# m52363b register map
Vendor: Elmos Semiconductor SE; Series: Integrated Driver; File version: 1.0
CPU: CM23 r1p0, little endian, MPU, no FPU, VTOR, 2 interrupt priority bits, 13 interrupts
Registers are 16-bit, read-write, reset 0x0 unless marked. A register's access mark holds for its fields unless they carry their own. Offsets are from the block's base; [hi:lo] are bit positions; {n}, {i} and the like mark numbered series; 'fields as' and 'values as' point back to an identical list.

## MOD_SECEXT — This instance contains registers for (core system level) module non-secure access protection
Base 0x45000020
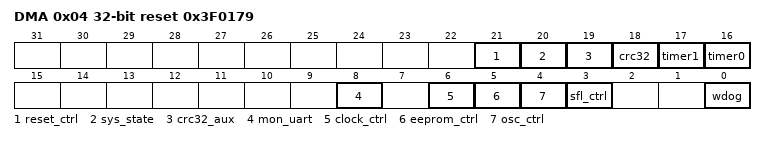
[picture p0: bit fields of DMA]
0x04 DMA 32-bit reset 0x3F0179
  [21] reset_ctrl — reset_ctrl bitfield
  [20] sys_state — sys_state bitfield
  [19] crc32_aux — crc32_aux bitfield
  [18] crc32 — crc32 bitfield
  [17] timer1 — timer1 bitfield
  [16] timer0 — timer0 bitfield
  [8] mon_uart — mon_uart bitfield
  [6] clock_ctrl — clock_ctrl bitfield
  [5] eeprom_ctrl — eeprom_ctrl bitfield
  [4] osc_ctrl — osc_ctrl bitfield
  [3] sfl_ctrl — sfl_ctrl bitfield
  [0] wdog — wdog bitfield

## MOD_SECEXT_CORE — This instance contains registers for (core level) module non-secure access protection
Base 0x45000028
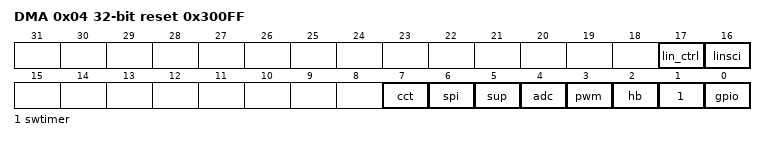
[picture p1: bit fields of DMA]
0x04 DMA 32-bit reset 0x300FF
  [17] lin_ctrl — lin_ctrl bitfield
  [16] linsci — linsci bitfield
  [7] cct — cct bitfield
  [6] spi — spi bitfield
  [5] sup — sup bitfield
  [4] adc — adc bitfield
  [3] pwm — pwm bitfield
  [2] hb — hb bitfield
  [1] swtimer — swtimer bitfield
  [0] gpio — gpio bitfield

## DMA_SEC_CRC16 — This instance contains registers for (core system level) DMA access protection.
Base 0x45000100
Same registers: DMA_SEC_CORE_LIN 0x45000180
0x00 AREA_BASE 32-bit
  [31:0] addr — addr bitfield
0x04 AREA_SIZE 32-bit
  [19:0] bytes — bytes bitfield
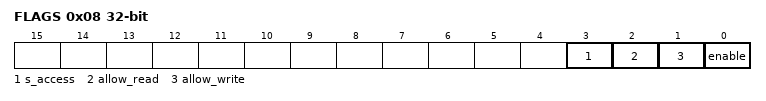
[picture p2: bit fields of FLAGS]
0x08 FLAGS 32-bit
  [3] s_access — s_access bitfield
  [2] allow_read — allow_read bitfield
  [1] allow_write — allow_write bitfield
  [0] enable — enable bitfield

## SEC_STATE — This instance contains registers for (core system level) DMA access error handling.
Base 0x45000200
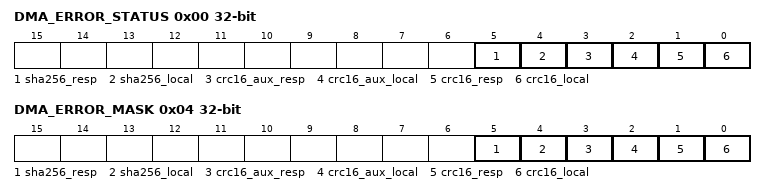
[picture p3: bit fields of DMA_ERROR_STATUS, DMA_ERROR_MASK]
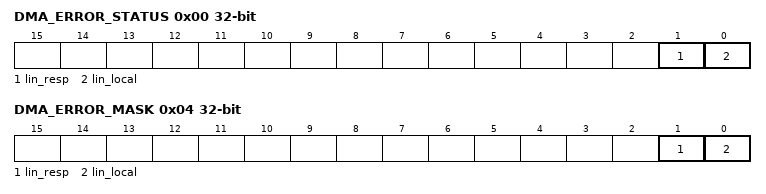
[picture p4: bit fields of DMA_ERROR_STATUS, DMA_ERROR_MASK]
0x00 DMA_ERROR_STATUS 32-bit
  [5] sha256_resp — sha256_resp bitfield
  [4] sha256_local — sha256_local bitfield
  [3] crc16_aux_resp — crc16_aux_resp bitfield
  [2] crc16_aux_local — crc16_aux_local bitfield
  [1] crc16_resp — crc16_resp bitfield
  [0] crc16_local — crc16_local bitfield
0x04 DMA_ERROR_MASK 32-bit
  fields as DMA_ERROR_STATUS

## SEC_STATE_CORE — This instance contains registers for (core level) DMA access error handling.
Base 0x45000210
0x00 DMA_ERROR_STATUS 32-bit
  [1] lin_resp — lin_resp bitfield
  [0] lin_local — lin_local bitfield
0x04 DMA_ERROR_MASK 32-bit
  fields as DMA_ERROR_STATUS

## SEC_VERSION
Base 0x45000220
0x00 VERSION 32-bit ro reset 0x1
  [31:0] version — version bitfield
0x04 MOD_SEC_VERSION 32-bit ro reset 0x1
  [31:0] version — version bitfield
0x08 MEM_SEC_VERSION 32-bit ro reset 0x1
  [31:0] version — version bitfield
0x0C DMA_SEC_VERSION 32-bit ro reset 0x1
  [31:0] version — version bitfield

## GPIO — GPIO module
Base 0x50000000
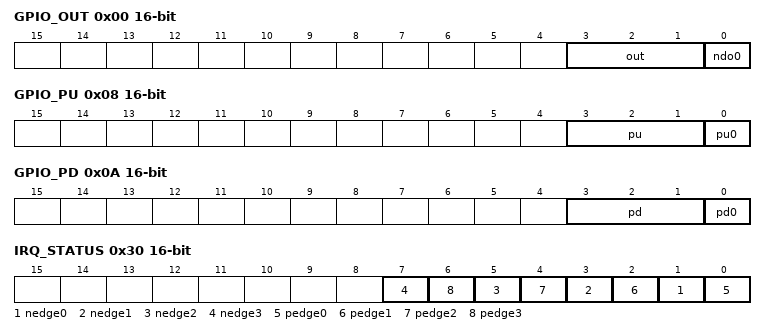
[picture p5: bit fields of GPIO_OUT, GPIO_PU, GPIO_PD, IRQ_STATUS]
0x00 GPIO_OUT
  [3:1] out — out bitfield
  [0] ndo0 — ndo0 bitfield
0x02 GPIO_OE
  [3:1] oe — oe bitfield
0x04 GPIO_IN ro
  [3:0] in — in bitfield
0x06 GPIO_DIG
  [3:0] dig — dig bitfield
0x08 GPIO_PU
  [3:1] pu — pu bitfield
  [0] pu0 — pu0 bitfield
0x0A GPIO_PD
  [3:1] pd — pd bitfield
  [0] pd0 — pd0 bitfield
0x0C TRIG_EDGE
  [3:0] te — te bitfield
0x0E CONFIG
  [2:0] set — set bitfield
0x30 IRQ_STATUS
  [2n+1] nedge{n} (n=0..3) — nedge{n} bitfield
  [2n] pedge{n} (n=0..3) — pedge{n} bitfield
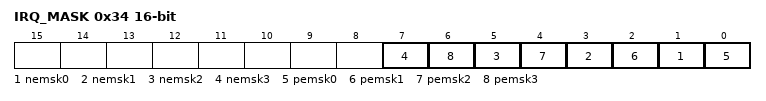
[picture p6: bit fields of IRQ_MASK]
0x34 IRQ_MASK
  [2n+1] nemsk{n} (n=0..3) — nemsk{n} bitfield
  [2n] pemsk{n} (n=0..3) — pemsk{n} bitfield
0x38 IRQ_VENABLE wo reset not defined
  [2:0] vno — vno bitfield
0x3A IRQ_VDISABLE wo reset not defined
  [2:0] vno — vno bitfield
0x3C IRQ_VMAX reset 0x8
  [3:0] vmax — vmax bitfield
0x3E IRQ_VNO reset 0x8
  [3:0] vno — vno bitfield

## SWTIMER — SWTIMER module
Base 0x50000100
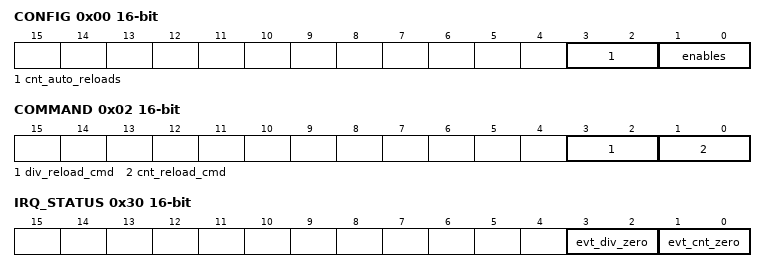
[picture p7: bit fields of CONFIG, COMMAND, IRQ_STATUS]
0x00 CONFIG
  [3:2] cnt_auto_reloads — cnt_auto_reloads bitfield
  [1:0] enables — enables bitfield
0x02 COMMAND wo reset not defined
  [3:2] div_reload_cmd — div_reload_cmd bitfield
  [1:0] cnt_reload_cmd — cnt_reload_cmd bitfield
0x04 CNT0_RELOAD
  [15:0] cnt_reload — cnt_reload bitfield
0x06 CNT1_RELOAD
  [15:0] cnt_reload — cnt_reload bitfield
0x08 DIV0_RELOAD
  [7:0] div_reload — div_reload bitfield
0x0A DIV1_RELOAD
  [7:0] div_reload — div_reload bitfield
0x0C CNT0_VALUE ro
  [15:0] cnt_val — cnt_val bitfield
0x0E CNT1_VALUE ro
  [15:0] cnt_val — cnt_val bitfield
0x30 IRQ_STATUS
  [3:2] evt_div_zero — evt_div_zero bitfield
  [1:0] evt_cnt_zero — evt_cnt_zero bitfield
0x34 IRQ_MASK
  [3:0] mask — mask bitfield
0x38 IRQ_VENABLE wo reset not defined
  [1:0] vno — vno bitfield
0x3A IRQ_VDISABLE wo reset not defined
  [1:0] vno — vno bitfield
0x3C IRQ_VMAX reset 0x4
  [2:0] vmax — vmax bitfield
0x3E IRQ_VNO reset 0x4
  [2:0] vno — vno bitfield
